# RE01_1500KB register map
Vendor: Renesas Electronics Corporation; Series: RE01_1500KB; File version: 1.20
CPU: CM0PLUS r0p1, little endian, MPU, no FPU, VTOR, 2 interrupt priority bits
Registers are 8-bit, read-write, reset 0x0 unless marked. A register's access mark holds for its fields unless they carry their own. Offsets are from the block's base; [hi:lo] are bit positions; {n}, {i} and the like mark numbered series; 'fields as' and 'values as' point back to an identical list.

## ICU — Interrupt Controller
Base 0x40006000
{0x0+i} IRQCR{i} (i=0..9) — IRQ Control Register {i}
  [1:0] IRQMD — IRQ Detection Sense Select
    0=Falling edge; 1=Rising edge; 2=Rising and falling edges; 3=Low level
0x100 NMICR — NMI Pin Interrupt Control Register
  [0] NMIMD — NMI Detection Set
    0=Falling edge; 1=Rising edge
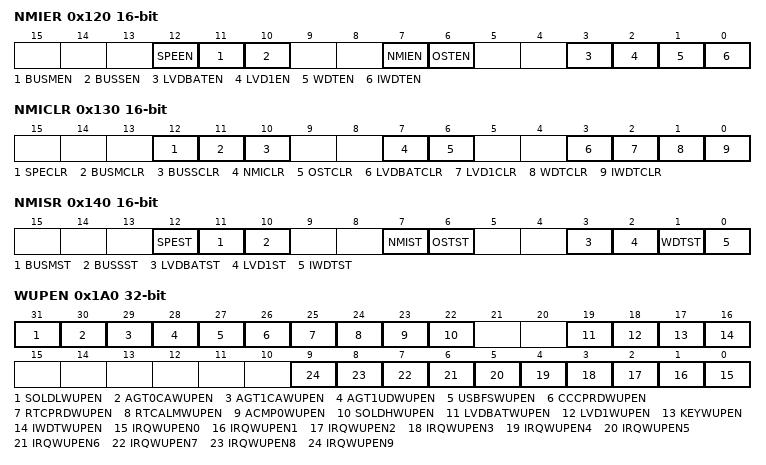
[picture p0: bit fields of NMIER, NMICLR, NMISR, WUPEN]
0x120 NMIER 16-bit — Non-Maskable Interrupt Enable Register
  [12] SPEEN
  [11] BUSMEN
  [10] BUSSEN
  [7] NMIEN — NMI Pin Interrupt Enable
    0=NMI pin interrupt is disabled; 1=NMI pin interrupt is enabled
  [6] OSTEN — Oscillation Stop Detection Interrupt Enable
    0=Main Oscillation stop detection interrupt is disabled; 1=Main Oscillation stop detection interrupt is enabled
  [3] LVDBATEN
  [2] LVD1EN — Voltage-Monitoring 1 Interrupt Enable
    0=Voltage-monitoring 1 interrupt is disabled; 1=Voltage-monitoring 1 interrupt is enabled
  [1] WDTEN — WDT Underflow/Refresh Error Interrupt Enable
    0=WDT underflow/refresh error interrupt is disabled; 1=WDT underflow/refresh error interrupt is enabled
  [0] IWDTEN — IWDT Underflow/Refresh Error Interrupt Enable
    0=IWDT underflow/refresh error interrupt is disabled; 1=IWDT underflow/refresh error interrupt is enabled
0x130 NMICLR 16-bit — Non-Maskable Interrupt Status Clear Register
  [12] SPECLR
  [11] BUSMCLR
  [10] BUSSCLR
  [7] NMICLR — NMIST Clear
    0=No effect; 1=Clear the NMISR.NMIST flag
  [6] OSTCLR — OSTST Clear
    0=No effect; 1=Clear the NMISR.OSTST flag
  [3] LVDBATCLR
  [2] LVD1CLR — LVD1ST Clear
    0=No effect; 1=Clear the NMISR.LVD1ST flag
  [1] WDTCLR — WDTST Clear
    0=No effect; 1=Clear the NMISR.WDTST flag
  [0] IWDTCLR — IWDTST Clear
    0=No effect; 1=Clear the NMISR.IWDTST flag
0x140 NMISR 16-bit ro — Non-Maskable Interrupt Status Register
  [12] SPEST
  [11] BUSMST
  [10] BUSSST
  [7] NMIST — NMI Status Flag
    0=NMI pin interrupt is not requested; 1=NMI pin interrupt is requested
  [6] OSTST — Oscillation Stop Detection Interrupt Status Flag
    0=Main Oscillation stop detection interrupt is not requested; 1=Main Oscillation stop detection interrupt is requested
  [3] LVDBATST
  [2] LVD1ST — Voltage-Monitoring 1 Interrupt Status Flag
    0=Voltage-monitoring 1 interrupt is not requested; 1=Voltage-monitoring 1 interrupt is requested
  [1] WDTST — WDT Underflow/Refresh Error Status Flag
    0=WDT underflow/refresh error interrupt is not requested; 1=WDT underflow/refresh error interrupt is requested
  [0] IWDTST — IWDT Underflow/Refresh Error Status Flag
    0=IWDT underflow/refresh error interrupt is not requested; 1=IWDT underflow/refresh error interrupt is requested
0x1A0 WUPEN 32-bit — Wake Up Interrupt Enable Register
  [31] SOLDLWUPEN
  [30] AGT0CAWUPEN — AGT0 compare match A interrupt S/W standby returns enable bit
    0=S/W standby returns by AGT0 compare match A interrupt is disabled; 1=S/W standby returns by AGT0 compare match A interrupt is enabled
  [29] AGT1CAWUPEN — AGT1 compare match A interrupt S/W standby returns enable bit
    0=S/W standby returns by AGT1 compare match A interrupt is disabled; 1=S/W standby returns by AGT1 compare match A interrupt is enabled
  [28] AGT1UDWUPEN — AGT1 underflow interrupt S/W standby returns enable bit
    0=S/W standby returns by AGT1 underflow interrupt is disabled; 1=S/W standby returns by AGT1 underflow interrupt is enabled
  [27] USBFSWUPEN — USBFS interrupt S/W standby returns enable bit
    0=S/W standby returns by USBFS interrupt is disabled; 1=S/W standby returns by USBFS interrupt is enabled
  [26] CCCPRDWUPEN — CCC period interrupt S/W standby returns enable bit
    0=S/W standby returns by CCC period interrupt is disabled; 1=S/W standby returns by CCC period interrupt is enabled
  [25] RTCPRDWUPEN — RCT period interrupt S/W standby returns enable bit
    0=S/W standby returns by RTC period interrupt is disabled; 1=S/W standby returns by RTC period interrupt is enabled
  [24] RTCALMWUPEN — RTC alarm interrupt S/W standby returns enable bit
    0=S/W standby returns by RTC alarm interrupt is disabled; 1=S/W standby returns by RTC alarm interrupt is enabled
  [23] ACMP0WUPEN — ACMP0 interrupt S/W standby returns enable bit
    0=S/W standby returns by ACMP0 interrupt is disabled; 1=S/W standby returns by ACMP0 interrupt is enabled
  [22] SOLDHWUPEN
  [19] LVDBATWUPEN — LVDBAT interrupt S/W standby returns enable bit
    0=S/W standby returns by LVDBAT interrupt is disabled; 1=S/W standby returns by LVDBAT interrupt is enabled
  [18] LVD1WUPEN — LVD1 interrupt S/W standby returns enable bit
    0=S/W standby returns by LVD1 interrupt is disabled; 1=S/W standby returns by LVD1 interrupt is enabled
  [17] KEYWUPEN — Key interrupt S/W standby returns enable bit
    0=S/W standby returns by KEY interrupt is disabled; 1=S/W standby returns by KEY interrupt is enabled
  [16] IWDTWUPEN — IWDT interrupt S/W standby returns enable bit
    0=S/W standby returns by IWDT interrupt is disabled; 1=S/W standby returns by IWDT interrupt is enabled
  [n] IRQWUPEN{n} (n=0..9) — IRQ{n} interrupt S/W standby returns enable bit
    0=S/W standby returns by IRQ{n} interrupt is disabled; 1=S/W standby returns by IRQ{n} interrupt is enabled
0x200 SELSR0 16-bit — SYS Event Link Setting Register
  [7:0] SELS — SYS Event Link Select
    0=Disable event output to the associated low-power mode module; other=others (Event signal number to be linked)
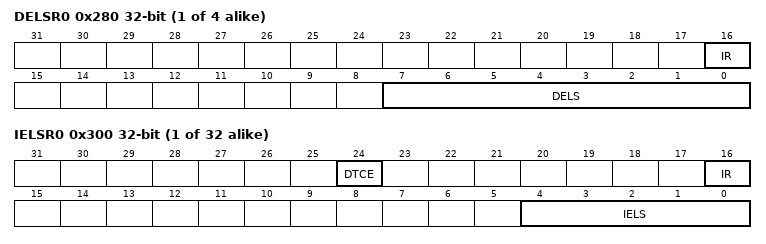
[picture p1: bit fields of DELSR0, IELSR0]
{0x280+4i} DELSR{i} (i=0..3) 32-bit
  [16] IR — Interrupt Status Flag
    0=No interrupt request is generated; 1=An interrupt request is generated ( 1 write to the IR bit is prohibited. )
  [7:0] DELS
{0x300+4i} IELSR{i} (i=0..31) 32-bit — ICU Event Link Setting Register {i}
  [24] DTCE — DTC Activation Enable
    0=DTC activation is disabled; 1=DTC activation is enabled
  [16] IR — Interrupt Status Flag
    values as DELSR0.IR
  [4:0] IELS
    0=0x000; other=others (See Event Table)
